AUTOSAR XML (schema 4-2-2)
package /Components
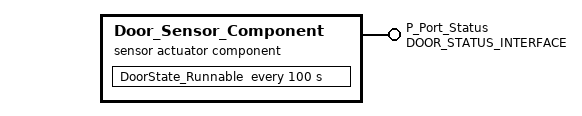
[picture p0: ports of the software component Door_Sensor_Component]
  sensor actuator sw component type Door_Sensor_Component
    provide port P_Port_Status: provided-interface=DOOR_STATUS_INTERFACE
    behavior Door_Sensor_Behavior: handle-termination-and-restart=true
      init event Init_E: start-on-event=DoorState_Runnable
      timing event Sample_Tick: start-on-event=DoorState_Runnable, period=100
      runnable DoorState_Runnable: can-be-invoked-concurrently=true, symbol=Door_Sensor_Status_Symbol
        data-receive-point-by-values:
          access DoorStatus_Receive: accessed-variable=P_Port_Status.ENVIRONMENT_DATA
        data-send-points:
          access DoorStatus_Send: accessed-variable=P_Port_Status.ENVIRONMENT_DATA
